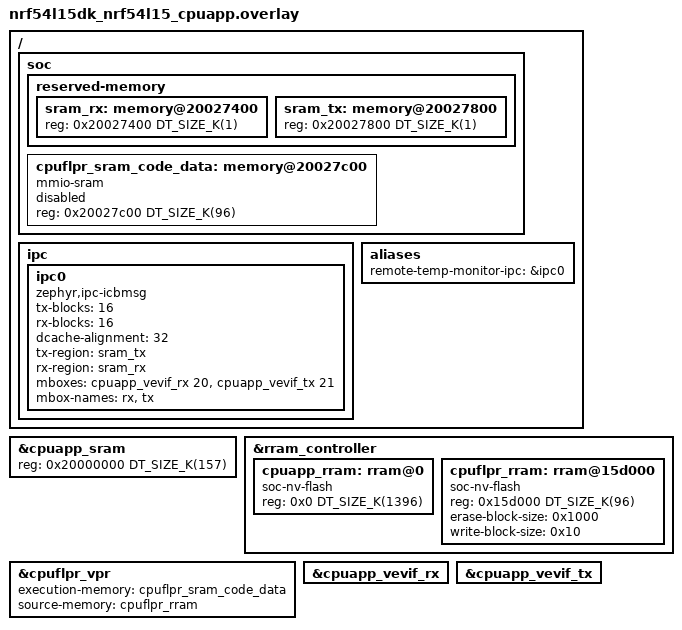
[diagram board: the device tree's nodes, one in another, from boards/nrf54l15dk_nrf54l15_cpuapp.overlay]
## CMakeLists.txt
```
#
# Copyright (c) 2026 Nordic Semiconductor ASA
#
# SPDX-License-Identifier: Apache-2.0
#

cmake_minimum_required(VERSION 3.20.0)

find_package(Zephyr REQUIRED HINTS $ENV{ZEPHYR_BASE})

project(shell_remote)

target_sources(app PRIVATE src/main.c)
```

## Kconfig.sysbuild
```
#
# Copyright (c) 2026 Nordic Semiconductor ASA
#
# SPDX-License-Identifier: Apache-2.0
#

config REMOTE_BOARD
	string
	default "$(BOARD)/nrf5340/cpunet" if BOARD_NRF5340DK_NRF5340_CPUAPP
	default "$(BOARD)/nrf5340/cpunet" if BOARD_NRF5340DK_NRF5340_CPUAPP_NS
	default "$(BOARD)/nrf5340/cpunet" if BOARD_NRF5340BSIM_NRF5340_CPUAPP
	# Unused when SOC is nRF54H20: sysbuild.cmake adds remote_rad, remote_ppr, remote_flpr.
	default "$(BOARD)/nrf54l15/cpuflpr" if SOC_NRF54L15_CPUAPP
	default "$(BOARD)/nrf54lm20a/cpuflpr" if SOC_NRF54LM20A_CPUAPP
	default "$(BOARD)/nrf54lv10a/cpuflpr" if SOC_NRF54LV10A_CPUAPP

source "share/sysbuild/Kconfig"
```

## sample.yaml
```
sample:
  name: Remote shell sample
tests:
  sample.shell_remote:
    sysbuild: true
    tags: ipc
    platform_allow:
      - nrf54l15dk/nrf54l15/cpuapp
      - nrf5340dk/nrf5340/cpuapp
      - nrf5340bsim/nrf5340/cpuapp
      - nrf54h20dk/nrf54h20/cpuapp
    integration_platforms:
      - nrf5340dk/nrf5340/cpuapp
      - nrf5340bsim/nrf5340/cpuapp
```

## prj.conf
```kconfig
CONFIG_PRINTK=y

CONFIG_IPC_SERVICE=y
CONFIG_PBUF_RX_READ_BUF_SIZE=256
CONFIG_MBOX=y

CONFIG_LOG=y
CONFIG_LOG_BUFFER_SIZE=16384
CONFIG_LOG_PRINTK=n
CONFIG_ASSERT=y

CONFIG_SHELL=y
CONFIG_SHELL_REMOTE=y

#CONFIG_NO_OPTIMIZATIONS=y
CONFIG_SHELL_STACK_SIZE=4096
CONFIG_SHELL_CMDS_SELECT=y
CONFIG_LOG_CMDS=y
```

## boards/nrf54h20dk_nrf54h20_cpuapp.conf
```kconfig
# Copyright (c) 2026 Nordic Semiconductor ASA
# SPDX-License-Identifier: Apache-2.0

CONFIG_SOC_NRF54H20_CPURAD_ENABLE=y
CONFIG_SHELL_REMOTE_PPR=y
CONFIG_SHELL_REMOTE_FLPR=y
CONFIG_SHELL_REMOTE_RADIO=y
```

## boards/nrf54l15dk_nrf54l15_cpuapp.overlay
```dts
/*
 * Copyright (c) 2026 Nordic Semiconductor ASA
 *
 * SPDX-License-Identifier: Apache-2.0
 */

/* 256k RAM layout:
   - 157k APP RAM
   - 2k APP-FLPR IPC communication
   - 96k FLPR Code
   - 1k FLPR Hibernation space
*/

/ {
	soc {
		reserved-memory {
			#address-cells = <1>;
			#size-cells = <1>;

			sram_rx: memory@20027400 {
				reg = <0x20027400 DT_SIZE_K(1)>;
			};

			sram_tx: memory@20027800 {
				reg = <0x20027800 DT_SIZE_K(1)>;
			};
		};

		cpuflpr_sram_code_data: memory@20027c00 {
			compatible = "mmio-sram";
			reg = <0x20027c00 DT_SIZE_K(96)>;
			ranges = <0x0 0x20027c00 DT_SIZE_K(96)>;
			status = "reserved";
			#address-cells = <1>;
			#size-cells = <1>;
		};
	};

	ipc {
		ipc0: ipc0 {
			compatible = "zephyr,ipc-icbmsg";
			tx-blocks = <16>;
			rx-blocks = <16>;
			dcache-alignment = <32>;
			tx-region = <&sram_tx>;
			rx-region = <&sram_rx>;
			mboxes = <&cpuapp_vevif_rx 20>, <&cpuapp_vevif_tx 21>;
			mbox-names = "rx", "tx";
			status = "okay";
		};
	};

	aliases {
		remote-temp-monitor-ipc = &ipc0;
	};
};

&cpuapp_sram {
	reg = <0x20000000 DT_SIZE_K(157)>;
	ranges = <0x0 0x20000000 DT_SIZE_K(157)>;
};

&rram_controller {
	cpuapp_rram: rram@0 {
		compatible = "soc-nv-flash";
		reg = <0x0 DT_SIZE_K(1396)>;
		ranges = <0x0 0 DT_SIZE_K(1396)>;
	};

	cpuflpr_rram: rram@15d000 {
		compatible = "soc-nv-flash";
		reg = <0x15d000 DT_SIZE_K(96)>;
		ranges = <0x0 0x15d000 DT_SIZE_K(96)>;
		erase-block-size = <0x1000>;
		write-block-size = <0x10>;
		#address-cells = <1>;
		#size-cells = <1>;
	};
};

&cpuflpr_vpr {
	status = "okay";
	execution-memory = <&cpuflpr_sram_code_data>;
	source-memory = <&cpuflpr_rram>;
};

&cpuapp_vevif_rx {
	status = "okay";
};

&cpuapp_vevif_tx {
	status = "okay";
};
```

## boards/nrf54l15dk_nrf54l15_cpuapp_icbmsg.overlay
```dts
/*
 * Copyright (c) 2026 Nordic Semiconductor ASA
 *
 * SPDX-License-Identifier: Apache-2.0
 */

/* 256k RAM layout:
   - 189k APP RAM
   - 2k APP-FLPR IPC communication
   - 64k FLPR Code
   - 1k FLPR Hibernation space
*/

/ {
	soc {
		reserved-memory {
			#address-cells = <1>;
			#size-cells = <1>;

			sram_rx: memory@2002f400 {
				reg = <0x2002f400 DT_SIZE_K(1)>;
			};

			sram_tx: memory@2002f800 {
				reg = <0x2002f800 DT_SIZE_K(1)>;
			};
		};

		cpuflpr_sram_code_data: memory@2002fc00 {
			compatible = "mmio-sram";
			reg = <0x2002fc00 DT_SIZE_K(64)>;
			ranges = <0x0 0x2002fc00 DT_SIZE_K(64)>;
			status = "reserved";
			#address-cells = <1>;
			#size-cells = <1>;
		};
	};

	ipc {
		ipc0: ipc0 {
			compatible = "zephyr,ipc-icbmsg";
			tx-blocks = <16>;
			rx-blocks = <16>;
			dcache-alignment = <32>;
			tx-region = <&sram_tx>;
			rx-region = <&sram_rx>;
			mboxes = <&cpuapp_vevif_rx 20>, <&cpuapp_vevif_tx 21>;
			mbox-names = "rx", "tx";
			status = "okay";
		};
	};

	aliases {
		remote-temp-monitor-ipc = &ipc0;
	};
};

&cpuapp_sram {
	reg = <0x20000000 DT_SIZE_K(189)>;
	ranges = <0x0 0x20000000 DT_SIZE_K(189)>;
};

&rram_controller {
	cpuflpr_rram: rram@165000 {
		compatible = "soc-nv-flash";
		reg = <0x165000 DT_SIZE_K(96)>;
		ranges = <0x0 0x165000 DT_SIZE_K(96)>;
		erase-block-size = <0x1000>;
		write-block-size = <0x10>;
		#address-cells = <1>;
		#size-cells = <1>;
	};
};

&cpuflpr_vpr {
	status = "okay";
	execution-memory = <&cpuflpr_sram_code_data>;
	source-memory = <&cpuflpr_rram>;
};

&cpuapp_vevif_rx {
	status = "okay";
};

&cpuapp_vevif_tx {
	status = "okay";
};
```

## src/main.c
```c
/*
 * Copyright (c) 2022 Nordic Semiconductor ASA
 *
 * SPDX-License-Identifier: Apache-2.0
 */

#include <zephyr/kernel.h>
#include <zephyr/logging/log.h>
LOG_MODULE_REGISTER(host, LOG_LEVEL_INF);

int main(void)
{
	LOG_INF("shell rpc host sample");
	return 0;
}
```
